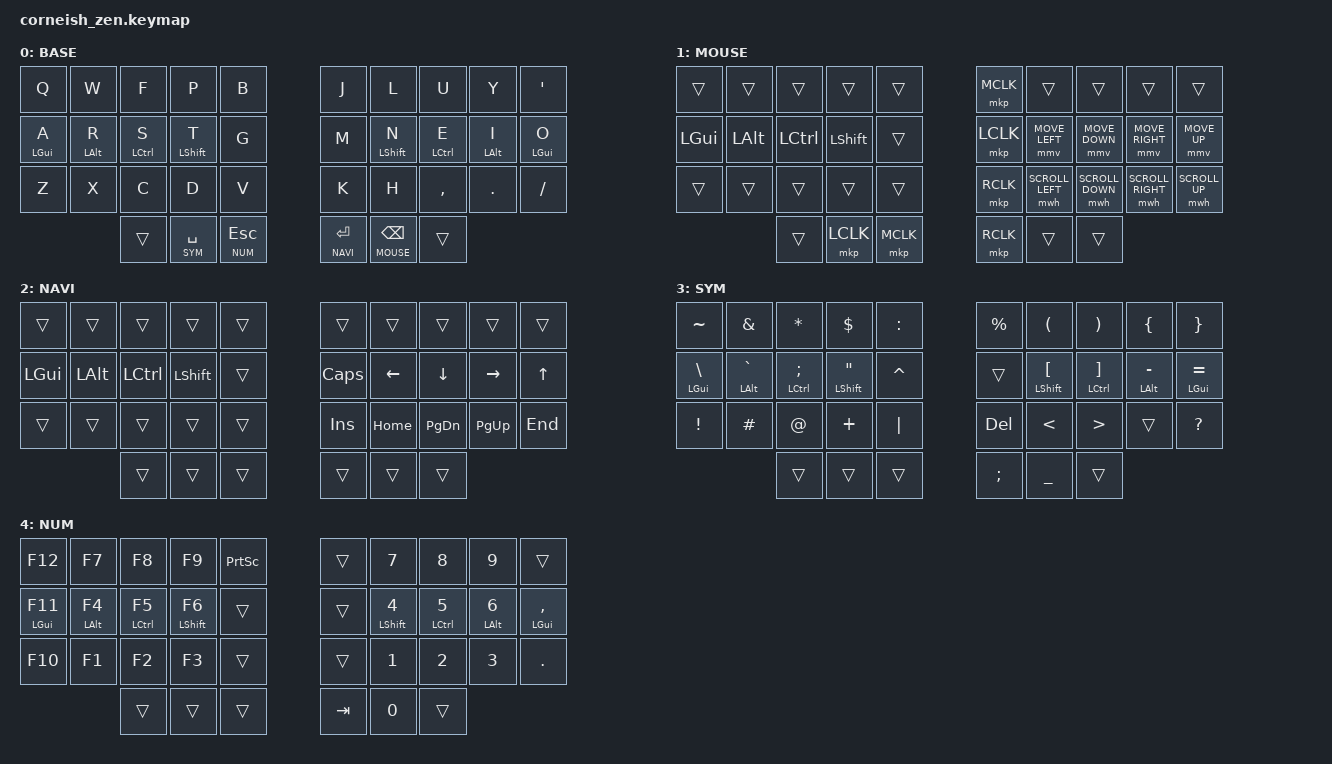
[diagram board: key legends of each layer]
#include <behaviors.dtsi>
#include <dt-bindings/zmk/keys.h>
#include <dt-bindings/zmk/bt.h>
#include <dt-bindings/zmk/mouse.h>

#define BASE 0
#define MOUSE 1
#define NAVI 2
#define SYM 3
#define NUM 4

#define U_MOUSE_MOVE_MAX 1000                     /* <--- New max speed setting (default: 600) */
#undef MOVE_UP
#undef MOVE_DOWN
#undef MOVE_LEFT
#undef MOVE_RIGHT
#define MOVE_UP MOVE_VERT(-U_MOUSE_MOVE_MAX)
#define MOVE_DOWN MOVE_VERT(U_MOUSE_MOVE_MAX)
#define MOVE_LEFT MOVE_HOR(-U_MOUSE_MOVE_MAX)
#define MOVE_RIGHT MOVE_HOR(U_MOUSE_MOVE_MAX)

#define U_MOUSE_SCROLL_MAX 20                    /* <--- New max speed setting (default: 10) */

#undef SCROLL_UP
#undef SCROLL_DOWN
#undef SCROLL_LEFT
#undef SCROLL_RIGHT
#define SCROLL_UP SCROLL_VERT(U_MOUSE_SCROLL_MAX)
#define SCROLL_DOWN SCROLL_VERT(-U_MOUSE_SCROLL_MAX)
#define SCROLL_LEFT SCROLL_HOR(-U_MOUSE_SCROLL_MAX)
#define SCROLL_RIGHT SCROLL_HOR(U_MOUSE_SCROLL_MAX)

/ {
  chosen {
    zmk,matrix_transform = &five_column_transform;
  };
};

/ {
    behaviors {
        hm: homerow_mods {
            compatible = "zmk,behavior-hold-tap";
            label = "HOMEROW_MODS";
            #binding-cells = <2>;
            tapping-term-ms = <2000>;
            // quick-tap-ms = <0>;
            // flavor = "tap-preferred";
            flavor = "balanced";
            bindings = <&kp>, <&kp>;
        };
    };

    keymap {
                compatible = "zmk,keymap";

                default_layer {
                        label = "BASE";
                        bindings = <
   &kp Q &kp W &kp F &kp P &kp B   &kp J &kp L  &kp U     &kp Y   &kp SQT
   &hm LGUI A &hm LALT R &hm LCTRL S &hm LSHIFT T &kp G   &kp M &hm LSHIFT N  &hm LCTRL E     &hm LALT I   &hm LGUI O
   &kp Z &kp X &kp C &kp D &kp V   &kp K &kp H  &kp COMMA &kp DOT &kp FSLH
                  &trans &lt SYM SPACE &lt NUM ESC  &lt NAVI RET &lt MOUSE BSPC &trans
                        >;
                };
                mouse_layer {
                        label = "MOUSE";
                        bindings = <
   &trans   &trans &trans   &trans   &trans      &mkp MCLK    &trans    &trans  &trans  &trans
   &kp LGUI   &kp LALT &kp LCTRL &kp LSHIFT &trans      &mkp LCLK &mmv MOVE_LEFT &mmv MOVE_DOWN &mmv MOVE_RIGHT &mmv MOVE_UP
   &trans   &trans &trans   &trans   &trans      &mkp RCLK &mwh SCROLL_LEFT &mwh SCROLL_DOWN &mwh SCROLL_RIGHT &mwh SCROLL_UP
                    	   &trans   &mkp LCLK &mkp MCLK   &mkp RCLK   &trans &trans
                        >;
                };

                navigation_layer {
                        label = "NAVI";
                        bindings = <
   &trans   &trans &trans   &trans   &trans      &trans    &trans    &trans  &trans  &trans
   &kp LGUI   &kp LALT &kp LCTRL &kp LSHIFT &trans      &kp CAPS &kp LEFT &kp DOWN &kp RIGHT &kp UP
   &trans   &trans &trans   &trans   &trans      &kp INS &kp HOME &kp PG_DN &kp PG_UP &kp END
                    	   &trans   &trans &trans   &trans   &trans &trans
                        >;
                };
                symbol_layer{
                        label = "SYM";
                        bindings = <
   &kp TILDE &kp AMPS &kp STAR &kp DLLR &kp COLON &kp PERCENT &kp LPAR &kp RPAR &kp LBRC &kp RBRC 
   &hm LGUI BSLH &hm LALT GRAVE &hm LCTRL SEMI &hm LSHIFT DQT &kp CARET &trans &hm LSHIFT LBKT &hm LCTRL RBKT  &hm LALT MINUS &hm LGUI EQUAL
   &kp EXCL &kp HASH &kp AT   &kp PLUS &kp PIPE &kp DEL &kp LT &kp GT &trans &kp QMARK
                    	     &trans &trans  &trans &kp SEMI  &kp UNDER &trans
                        >;
                };
                number_layer{
                        label = "NUM";
                        bindings = <
   &kp F12 &kp F7 &kp F8 &kp F9 &kp PSCRN   &trans &kp N7  &kp N8 &kp N9 &trans
   &hm LGUI F11 &hm LALT F4 &hm LCTRL F5 &hm LSHIFT F6  &trans &trans &hm LSHIFT N4 &hm LCTRL N5 &hm LALT N6 &hm LGUI COMMA
   &kp F10   &kp F1 &kp F2   &kp F3   &trans      &trans &kp N1 &kp N2 &kp N3 &kp DOT
                    	     &trans &trans   &trans &kp TAB &kp N0 &trans
                        >;
                };
        };
};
